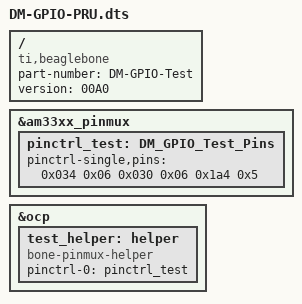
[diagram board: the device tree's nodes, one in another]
/*  
* Copyright (C) 2012 Texas Instruments Incorporated - http://www.ti.com/
*
* This program is free software; you can redistribute it and/or modify
* it under the terms of the GNU General Purpose License Version 2 as
* published by the Free Software Foundation
*
* Original from: github.com/jadonk/validation-scripts/blob/master/test-capemgr/ 
*  Edited by icepic2009@googlemail.com
*
*  Enable fast access to gpio pins on pru 
*/

/dts-v1/;
/plugin/;

/{
       compatible = "ti,beaglebone", "ti,beaglebone-black";
       part-number = "DM-GPIO-Test";
       version = "00A0";

       fragment@0 {
             target = <&am33xx_pinmux>;
            
             __overlay__ {
                  pinctrl_test: DM_GPIO_Test_Pins {
			pinctrl-single,pins = <
			   0x034 0x06  /* Set P8_11 to Mode 6 => r30_15 */
			   0x030 0x06  /* Set P8_12 to Mode 6 => r30_14 */
			   0x1a4 0x5   /* Set P9_27 to Mode 5 => r30_5  */
			>;
		  };
             };
       };

       fragment@1 {
		target = <&ocp>;
		__overlay__ {
			test_helper: helper {
				compatible = "bone-pinmux-helper";
				pinctrl-names = "default";
				pinctrl-0 = <&pinctrl_test>;
				status = "okay";
			};
		};
	};
};
